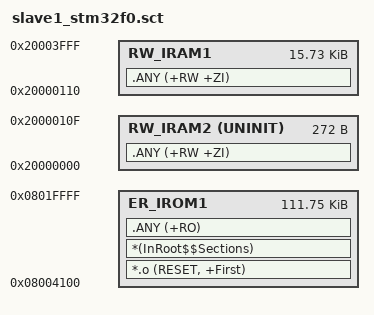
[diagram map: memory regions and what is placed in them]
; *************************************************************
; *** Scatter-Loading Description File generated by uVision ***
; *************************************************************

LR_IROM1 0x08004100 0x0001BF00  {    ; load region size_region
  ER_IROM1 0x08004100 0x0001BF00  {  ; load address = execution address
   *.o (RESET, +First)
   *(InRoot$$Sections)
   .ANY (+RO)
  }
  RW_IRAM1 0x20000110 0x00003EF0  {  ; RW data
   .ANY (+RW +ZI)
  }
  RW_IRAM2 0x20000000 UNINIT 0x00000110  {
   .ANY (+RW +ZI)
  }
}

